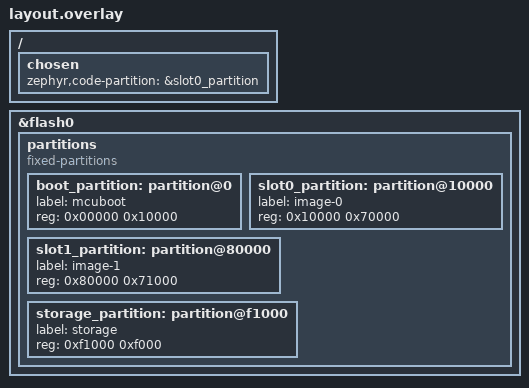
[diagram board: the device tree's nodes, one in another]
/ {
    chosen { zephyr,code-partition = &slot0_partition; };
};

&flash0 {
    partitions {
        compatible = "fixed-partitions";
        #address-cells = <1>;
        #size-cells = <1>;
        boot_partition: partition@0 {
            label = "mcuboot";
            reg = <0x00000 0x10000>;
        };
        slot0_partition: partition@10000 {
            label = "image-0";
            reg = <0x10000 0x70000>;
        };
        /* Offset swap needs one additional 4 KiB sector in the secondary. */
        slot1_partition: partition@80000 {
            label = "image-1";
            reg = <0x80000 0x71000>;
        };
        storage_partition: partition@f1000 {
            label = "storage";
            reg = <0xf1000 0xf000>;
        };
    };
};
